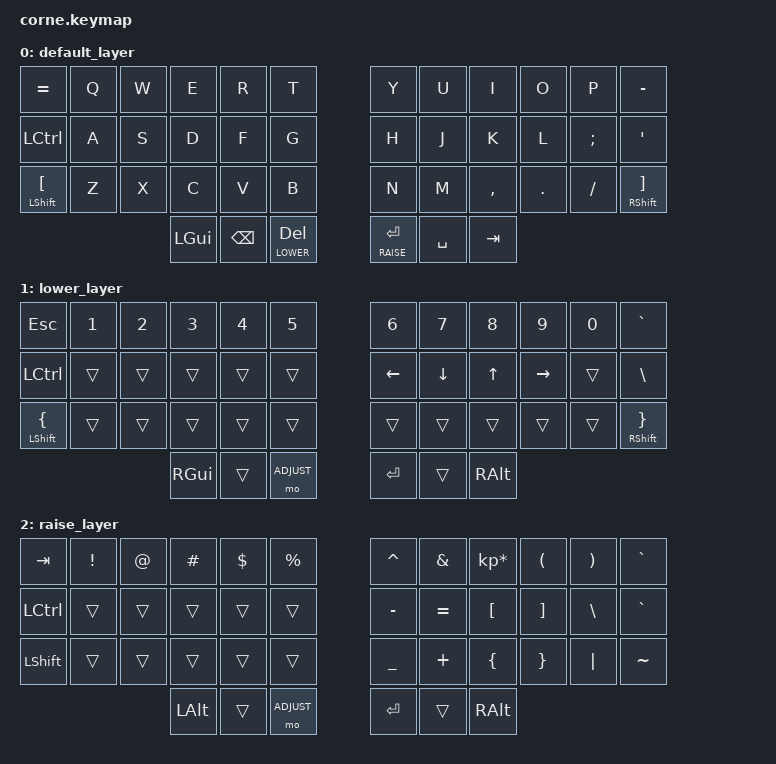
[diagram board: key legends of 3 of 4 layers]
/*
 * Copyright (c) 2020 The ZMK Contributors
 *
 * SPDX-License-Identifier: MIT
 */

#include <behaviors.dtsi>
#include <dt-bindings/zmk/keys.h>
#include <dt-bindings/zmk/bt.h>
#define DEFAULT 0
#define LOWER   1
#define RAISE   2
#define ADJUST  3
&mt {    tapping-term-ms = <450>;};
/ {
        keymap {
                compatible = "zmk,keymap";

                default_layer {
// -----------------------------------------------------------------------------------------
// |  TAB |  Q  |  W  |  E  |  R  |  T  |   |  Y  |  U   |  I  |  O  |  P  | BKSP |
// | CTRL |  A  |  S  |  D  |  F  |  G  |   |  H  |  J   |  K  |  L  |  ;  |  '   |
// | SHFT |  Z  |  X  |  C  |  V  |  B  |   |  N  |  M   |  ,  |  .  |  /  | ESC  |
//                    | GUI | LWR | SPC |   | ENT | RSE  | ALT |
                        bindings = <
   &kp EQUAL   &kp Q &kp W &kp E &kp R &kp T   &kp Y &kp U  &kp I     &kp O   &kp P    &kp MINUS
   &kp LCTRL &kp A &kp S &kp D &kp F &kp G   &kp H &kp J  &kp K     &kp L   &kp SEMI &kp SQT
   &mt LSHIFT LEFT_BRACKET &kp Z &kp X &kp C &kp V &kp B   &kp N &kp M  &kp COMMA &kp DOT &kp FSLH &mt RIGHT_SHIFT RIGHT_BRACKET
                  &kp LGUI &kp BSPC &lt LOWER DEL   &lt RAISE RET &kp SPACE &kp TAB
                        >;
                };
                lower_layer {
// -----------------------------------------------------------------------------------------
// |  TAB |  1  |  2  |  3  |  4  |  5  |   |  6  |  7  |  8  |  9  |  0  | BKSP |
// | BTCLR| BT1 | BT2 | BT3 | BT4 | BT5 |   | LFT | DWN |  UP | RGT |     |      |
// | SHFT |     |     |     |     |     |   |     |     |     |     |     |      |
//                    | GUI |     | SPC |   | ENT |     | ALT |
                        bindings = <
   &kp ESCAPE    &kp N1       &kp N2       &kp N3       &kp N4       &kp N5         &kp N6   &kp N7   &kp N8 &kp N9    &kp N0 &kp GRAVE
   &kp LCTRL &trans &trans &trans &trans &trans   &kp LEFT &kp DOWN &kp UP &kp RIGHT &trans &kp BSLH
   &mt LSHIFT LEFT_BRACE  &trans  &trans   &trans  &trans  &trans &trans   &trans   &trans &trans    &trans &mt RIGHT_SHIFT RIGHT_BRACE
                          	        &kp RGUI     &trans       &mo ADJUST      &kp RET  &trans   &kp RALT
                        >;
                };

                raise_layer {
// -----------------------------------------------------------------------------------------
// |  TAB |  !  |  @  |  #  |  $  |  %  |   |  ^  |  &  |  *  |  (  |  )  | BKSP |
// | CTRL |     |     |     |     |     |   |  -  |  =  |  [  |  ]  |  \  |  `   |
// | SHFT |     |     |     |     |     |   |  _  |  +  |  {  |  }  | "|" |  ~   |
//                    | GUI |     | SPC |   | ENT |     | ALT |
                        bindings = <
   &kp  TAB  &kp EXCL &kp AT &kp HASH &kp DLLR &kp PRCNT   &kp CARET &kp AMPS  &kp KP_MULTIPLY &kp LPAR &kp RPAR &kp GRAVE
   &kp LCTRL &trans   &trans &trans   &trans   &trans      &kp MINUS &kp EQUAL &kp LBKT        &kp RBKT &kp BSLH &kp GRAVE
   &kp LSHFT &trans   &trans &trans   &trans   &trans      &kp UNDER &kp PLUS  &kp LBRC        &kp RBRC &kp PIPE &kp TILDE
                    	     &kp LALT &trans   &mo ADJUST   &kp RET   &trans    &kp RALT
                        >;
                };

  adjust_layer {
// -----------------------------------------------------------------------------------------
// |  bt next |  bt 1  |  bt2  |  bt3  |  bt4  |  bt5  |   |  ^  |  &  |  *  |  (  |  )  | BKSP |
// | CTRL |     |     |     |     |     |   |  -  |  =  |  [  |  ]  |  \  |  `   |
// | SHFT |     |     |     |     |  bt clr |   |  _  |  +  |  {  |  }  | "|" |  ~   |
//                    | GUI |     | SPC |   | ENT |     | ALT |
                                        bindings = <
                   &bt BT_NXT  &bt BT_SEL 0 &bt BT_SEL 1 &bt BT_SEL 2 &bt BT_SEL 3 &bt BT_SEL 4   &kp CARET &kp AMPS  &kp KP_MULTIPLY &kp LPAR &kp RPAR &kp BSPC
                   &trans &trans   &trans &trans   &trans   &trans      &kp MINUS &kp EQUAL &kp LBKT        &kp RBKT &kp BSLH &kp GRAVE
                   &trans   &trans &bt BT_CLR  &reset   &trans      &kp UNDER &kp PLUS  &kp LBRC        &kp RBRC &kp PIPE &kp TILDE

                                    	     &kp LGUI &trans   &kp SPACE   &kp RET   &trans    &kp RALT
                                        >;
                                };
        };
};
